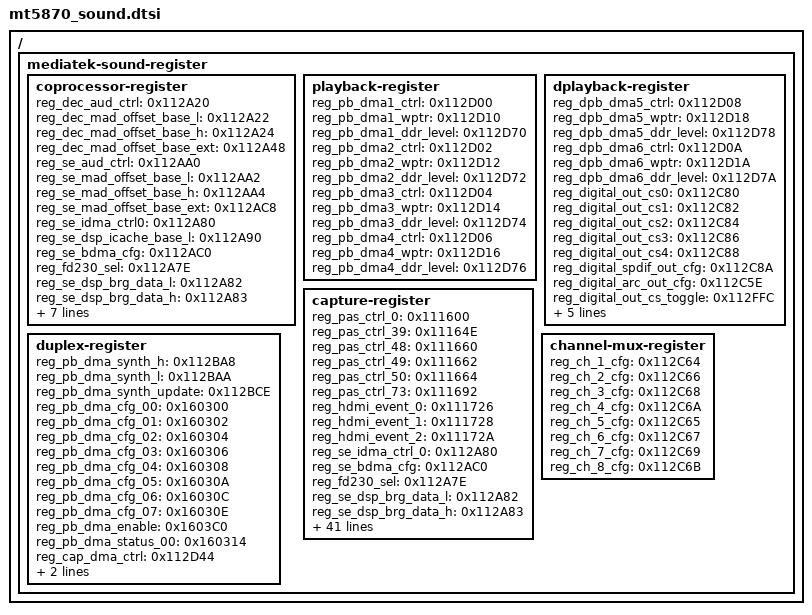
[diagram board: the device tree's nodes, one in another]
// SPDX-License-Identifier: GPL-2.0

/ {
	mediatek-sound-register {
		coprocessor-register {
			reg_dec_aud_ctrl = <0x112A20>;
			reg_dec_mad_offset_base_l = <0x112A22>;
			reg_dec_mad_offset_base_h = <0x112A24>;
			reg_dec_mad_offset_base_ext = <0x112A48>;
			reg_se_aud_ctrl = <0x112AA0>;
			reg_se_mad_offset_base_l = <0x112AA2>;
			reg_se_mad_offset_base_h = <0x112AA4>;
			reg_se_mad_offset_base_ext = <0x112AC8>;
			reg_se_idma_ctrl0 = <0x112A80>;
			reg_se_dsp_icache_base_l = <0x112A90>;
			reg_se_bdma_cfg = <0x112AC0>;
			reg_fd230_sel = <0x112A7E>;
			reg_se_dsp_brg_data_l = <0x112A82>;
			reg_se_dsp_brg_data_h = <0x112A83>;
			reg_se_idma_wrbase_addr_l = <0x112A84>;
			reg_riu_mail_00 = <0x112B40>;
			reg_dsp_power_down_h = <0x112D31>;
			reg_dsp_dbg_cmd1 = <0x112DDC>;
			reg_dsp_isr_cntr = <0x112DF7>;
			reg_dsp_while1_cntr = <0x112DF8>;
			reg_dsp_dbg_result1 = <0x112DFC>;
		};
		playback-register {
			reg_pb_dma1_ctrl = <0x112D00>;
			reg_pb_dma1_wptr = <0x112D10>;
			reg_pb_dma1_ddr_level = <0x112D70>;
			reg_pb_dma2_ctrl = <0x112D02>;
			reg_pb_dma2_wptr = <0x112D12>;
			reg_pb_dma2_ddr_level = <0x112D72>;
			reg_pb_dma3_ctrl = <0x112D04>;
			reg_pb_dma3_wptr = <0x112D14>;
			reg_pb_dma3_ddr_level = <0x112D74>;
			reg_pb_dma4_ctrl = <0x112D06>;
			reg_pb_dma4_wptr = <0x112D16>;
			reg_pb_dma4_ddr_level = <0x112D76>;
		};
		dplayback-register {
			reg_dpb_dma5_ctrl = <0x112D08>;
			reg_dpb_dma5_wptr = <0x112D18>;
			reg_dpb_dma5_ddr_level = <0x112D78>;
			reg_dpb_dma6_ctrl = <0x112D0A>;
			reg_dpb_dma6_wptr = <0x112D1A>;
			reg_dpb_dma6_ddr_level = <0x112D7A>;
			reg_digital_out_cs0 = <0x112C80>;
			reg_digital_out_cs1 = <0x112C82>;
			reg_digital_out_cs2 = <0x112C84>;
			reg_digital_out_cs3 = <0x112C86>;
			reg_digital_out_cs4 = <0x112C88>;
			reg_digital_spdif_out_cfg = <0x112C8A>;
			reg_digital_arc_out_cfg = <0x112C5E>;
			reg_digital_out_cs_toggle = <0x112FFC>;
			reg_digital_out_spdif_synth_h = <0x112BB8>;
			reg_digital_out_spdif_synth_l = <0x112BBA>;
			reg_digital_out_arc_synth_h = <0x112BD0>;
			reg_digital_out_arc_synth_l = <0x112BD2>;
			reg_digital_out_synth_cfg = <0x112BCE>;
		};
		capture-register {
			reg_pas_ctrl_0 = <0x111600>;
			reg_pas_ctrl_39 = <0x11164E>;
			reg_pas_ctrl_48 = <0x111660>;
			reg_pas_ctrl_49 = <0x111662>;
			reg_pas_ctrl_50 = <0x111664>;
			reg_pas_ctrl_73 = <0x111692>;
			reg_hdmi_event_0 = <0x111726>;
			reg_hdmi_event_1 = <0x111728>;
			reg_hdmi_event_2 = <0x11172A>;
			reg_se_idma_ctrl_0 = <0x112A80>;
			reg_se_bdma_cfg = <0x112AC0>;
			reg_fd230_sel = <0x112A7E>;
			reg_se_dsp_brg_data_l = <0x112A82>;
			reg_se_dsp_brg_data_h = <0x112A83>;
			reg_se_idma_wrbase_addr_l = <0x112A84>;
			reg_se_idma_rdbase_addr_l = <0x112A88>;
			reg_se_idma_rddata_h_0 = <0x112A8c>;
			reg_se_idma_rddata_h_1 = <0x112A8d>;
			reg_se_idma_rddata_l = <0x112A8e>;
			reg_se_aud_ctrl = <0x112AA0>;
			reg_se_mbase_h = <0x112AA6>;
			reg_se_msize_h = <0x112AA8>;
			reg_se_mcfg = <0x112AAA>;
			reg_se_mbase_ext = <0x112ACA>;
			reg_input_cfg = <0x112C02>;
			reg_status_input = <0x112C0C>;
			reg_status_hdmi_pc = <0x112C40>;
			reg_new_mode_cfg = <0x112C48>;
			reg_decoder1_cfg = <0x112C60>;
			reg_mute_ctrl1 = <0x112C94>;
			reg_clk_cfg6 = <0x112CB0>;
			reg_sif_agc_cfg6 = <0x112CC6>;
			reg_asif_amux = <0x112CC8>;
			reg_cap_dma1_ctrl = <0x112D40>;
			reg_cap_dma1_rptr = <0x112D50>;
			reg_cap_dma1_wptr = <0x112DF0>;
			reg_cap_dma2_ctrl = <0x112D42>;
			reg_cap_dma2_rptr = <0x112D52>;
			reg_cap_dma2_wptr = <0x112DF2>;
			reg_cap_dma4_ctrl = <0x112D46>;
			reg_cap_dma4_rptr = <0x112D56>;
			reg_cap_dma4_wptr = <0x112D7E>;
			reg_atv_play_cmd = <0x112AAC>;
			reg_atv_std_cmd = <0x112DC0>;
			reg_atv_comm_cfg = <0x112DC2>;
			reg_atv_snd_mode_1 = <0x112DC4>;
			reg_atv_snd_mode_2 = <0x112DC6>;
			reg_atv_detection_result = <0x112DE0>;
			reg_atv_snd_carrier_status_1 = <0x112DE4>;
			reg_atv_snd_carrier_status_2 = <0x112DE6>;
			reg_dbg_cmd_1 = <0x112DDC>;
			reg_dbg_cmd_2 = <0x112DDE>;
			reg_dbg_result_1 = <0x112DFC>;
			reg_dbg_result_2 = <0x112DFE>;
			reg_se_aid_ctrl = <0x112E3E>;
		};
		duplex-register {
			reg_pb_dma_synth_h = <0x112BA8>;
			reg_pb_dma_synth_l = <0x112BAA>;
			reg_pb_dma_synth_update = <0x112BCE>;
			reg_pb_dma_cfg_00 = <0x160300>;
			reg_pb_dma_cfg_01 = <0x160302>;
			reg_pb_dma_cfg_02 = <0x160304>;
			reg_pb_dma_cfg_03 = <0x160306>;
			reg_pb_dma_cfg_04 = <0x160308>;
			reg_pb_dma_cfg_05 = <0x16030A>;
			reg_pb_dma_cfg_06 = <0x16030C>;
			reg_pb_dma_cfg_07 = <0x16030E>;
			reg_pb_dma_enable = <0x1603C0>;
			reg_pb_dma_status_00 = <0x160314>;
			reg_cap_dma_ctrl = <0x112D44>;
			reg_cap_dma_rptr = <0x112D54>;
			reg_cap_dma_wptr = <0x112DF4>;
		};
		channel-mux-register {
			reg_ch_1_cfg = <0x112C64>;
			reg_ch_2_cfg = <0x112C66>;
			reg_ch_3_cfg = <0x112C68>;
			reg_ch_4_cfg = <0x112C6A>;
			reg_ch_5_cfg = <0x112C65>;
			reg_ch_6_cfg = <0x112C67>;
			reg_ch_7_cfg = <0x112C69>;
			reg_ch_8_cfg = <0x112C6B>;
		};
	};
};
